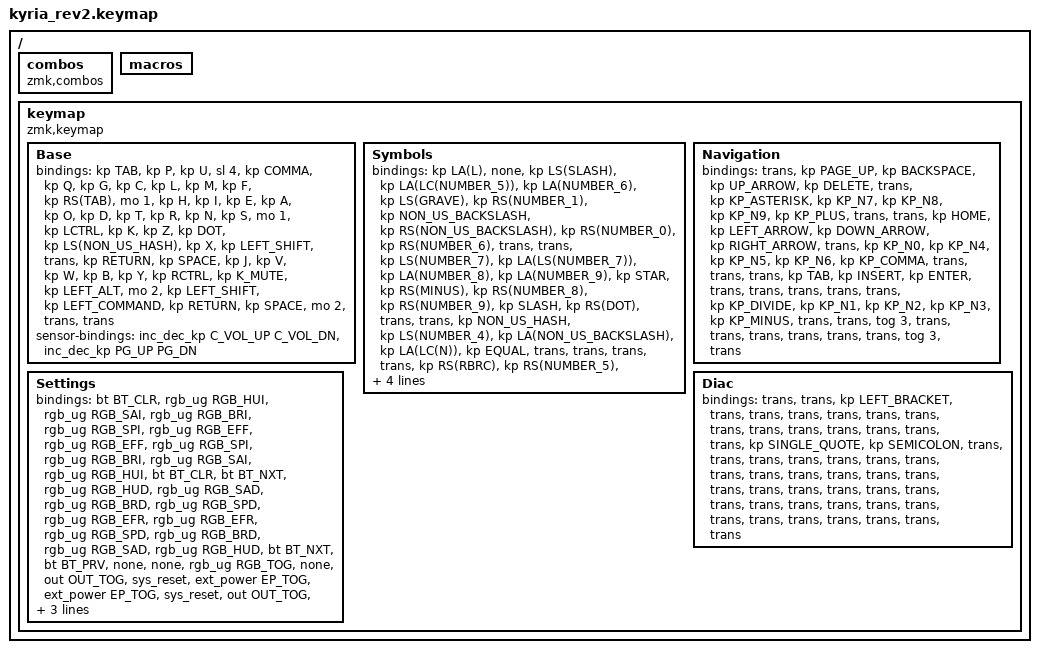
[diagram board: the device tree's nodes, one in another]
/*
 * Copyright (c) 2020 The ZMK Contributors
 *
 * SPDX-License-Identifier: MIT
 */

#include <behaviors.dtsi>
#include <dt-bindings/zmk/keys.h>
#include <dt-bindings/zmk/bt.h>
#include <dt-bindings/zmk/rgb.h>
#include <dt-bindings/zmk/outputs.h>
#include <dt-bindings/zmk/ext_power.h>

/ {
    combos {
        compatible = "zmk,combos";
    };

    macros {
    };

    keymap {
        compatible = "zmk,keymap";

        Base {
            // ---------------------------------------------------------------------------------------------------------------------------------
            // |  ESC  |  Q  |  W  |  E   |  R   |  T   |                                          |  Y   |  U    |  I    |  O   |   P   |   \  |
            // |  TAB  |  A  |  S  |  D   |  F   |  G   |                                          |  H   |  J    |  K    |  L   |   ;   |   '  |
            // | SHIFT |  Z  |  X  |  C   |  V   |  B   | L SHIFT | L SHIFT |  | L SHIFT | L SHIFT |  N   |  M    |  ,    |  .   |   /   | CTRL |
            //                     | GUI  | DEL  | RET  |  SPACE  |   ESC   |  |   RET   |  SPACE  | TAB  | BSPC  | R-ALT |

            bindings = <
&kp TAB  &kp P  &kp U  &sl 4  &kp COMMA  &kp Q  &kp G  &kp C  &kp L  &kp M  &kp F  &kp RS(TAB)  &mo 1  &kp H  &kp I  &kp E  &kp A  &kp O  &kp D  &kp T  &kp R  &kp N  &kp S  &mo 1  &kp LCTRL  &kp K  &kp Z  &kp DOT  &kp LS(NON_US_HASH)  &kp X  &kp LEFT_SHIFT  &trans  &kp RETURN  &kp SPACE  &kp J  &kp V  &kp W  &kp B  &kp Y  &kp RCTRL  &kp K_MUTE  &kp LEFT_ALT  &mo 2  &kp LEFT_SHIFT  &kp LEFT_COMMAND  &kp RETURN  &kp SPACE  &mo 2  &trans  &trans
            >;

            sensor-bindings = <&inc_dec_kp C_VOL_UP C_VOL_DN &inc_dec_kp PG_UP PG_DN>;
        };

        Symbols {
            bindings = <
&kp LA(L)  &none  &kp LS(SLASH)  &kp LA(LC(NUMBER_5))  &kp LA(NUMBER_6)  &kp LS(GRAVE)  &kp RS(NUMBER_1)  &kp NON_US_BACKSLASH  &kp RS(NON_US_BACKSLASH)  &kp RS(NUMBER_0)  &kp RS(NUMBER_6)  &trans  &trans  &kp LS(NUMBER_7)  &kp LA(LS(NUMBER_7))  &kp LA(NUMBER_8)  &kp LA(NUMBER_9)  &kp STAR  &kp RS(MINUS)  &kp RS(NUMBER_8)  &kp RS(NUMBER_9)  &kp SLASH  &kp RS(DOT)  &trans  &trans  &kp NON_US_HASH  &kp LS(NUMBER_4)  &kp LA(NON_US_BACKSLASH)  &kp LA(LC(N))  &kp EQUAL  &trans  &trans  &trans  &trans  &kp RS(RBRC)  &kp RS(NUMBER_5)  &kp RS(NUMBER_2)  &kp RS(NON_US_HASH)  &kp RS(COMMA)  &trans  &trans  &trans  &trans  &trans  &trans  &trans  &trans  &trans  &trans  &trans
            >;
        };

        Navigation {
            bindings = <
&trans  &kp PAGE_UP  &kp BACKSPACE  &kp UP_ARROW  &kp DELETE  &trans  &kp KP_ASTERISK  &kp KP_N7  &kp KP_N8  &kp KP_N9  &kp KP_PLUS  &trans  &trans  &kp HOME  &kp LEFT_ARROW  &kp DOWN_ARROW  &kp RIGHT_ARROW  &trans  &kp KP_N0  &kp KP_N4  &kp KP_N5  &kp KP_N6  &kp KP_COMMA  &trans  &trans  &trans  &kp TAB  &kp INSERT  &kp ENTER  &trans  &trans  &trans  &trans  &trans  &kp KP_DIVIDE  &kp KP_N1  &kp KP_N2  &kp KP_N3  &kp KP_MINUS  &trans  &trans  &tog 3  &trans  &trans  &trans  &trans  &trans  &trans  &tog 3  &trans
            >;
        };

        Settings {
            bindings = <
&bt BT_CLR  &rgb_ug RGB_HUI  &rgb_ug RGB_SAI  &rgb_ug RGB_BRI  &rgb_ug RGB_SPI  &rgb_ug RGB_EFF  &rgb_ug RGB_EFF  &rgb_ug RGB_SPI  &rgb_ug RGB_BRI  &rgb_ug RGB_SAI  &rgb_ug RGB_HUI  &bt BT_CLR  &bt BT_NXT  &rgb_ug RGB_HUD  &rgb_ug RGB_SAD  &rgb_ug RGB_BRD  &rgb_ug RGB_SPD  &rgb_ug RGB_EFR  &rgb_ug RGB_EFR  &rgb_ug RGB_SPD  &rgb_ug RGB_BRD  &rgb_ug RGB_SAD  &rgb_ug RGB_HUD  &bt BT_NXT  &bt BT_PRV  &none  &none  &rgb_ug RGB_TOG  &none  &out OUT_TOG  &sys_reset  &ext_power EP_TOG  &ext_power EP_TOG  &sys_reset  &out OUT_TOG  &none  &rgb_ug RGB_TOG  &none  &none  &bt BT_PRV  &none  &tog 3  &none  &sys_reset  &bootloader  &bootloader  &sys_reset  &none  &tog 3  &none
            >;
        };

        Diac {
            bindings = <
&trans  &trans  &kp LEFT_BRACKET  &trans  &trans  &trans  &trans  &trans  &trans  &trans  &trans  &trans  &trans  &trans  &trans  &trans  &kp SINGLE_QUOTE  &kp SEMICOLON  &trans  &trans  &trans  &trans  &trans  &trans  &trans  &trans  &trans  &trans  &trans  &trans  &trans  &trans  &trans  &trans  &trans  &trans  &trans  &trans  &trans  &trans  &trans  &trans  &trans  &trans  &trans  &trans  &trans  &trans  &trans  &trans
            >;
        };
    };
};
